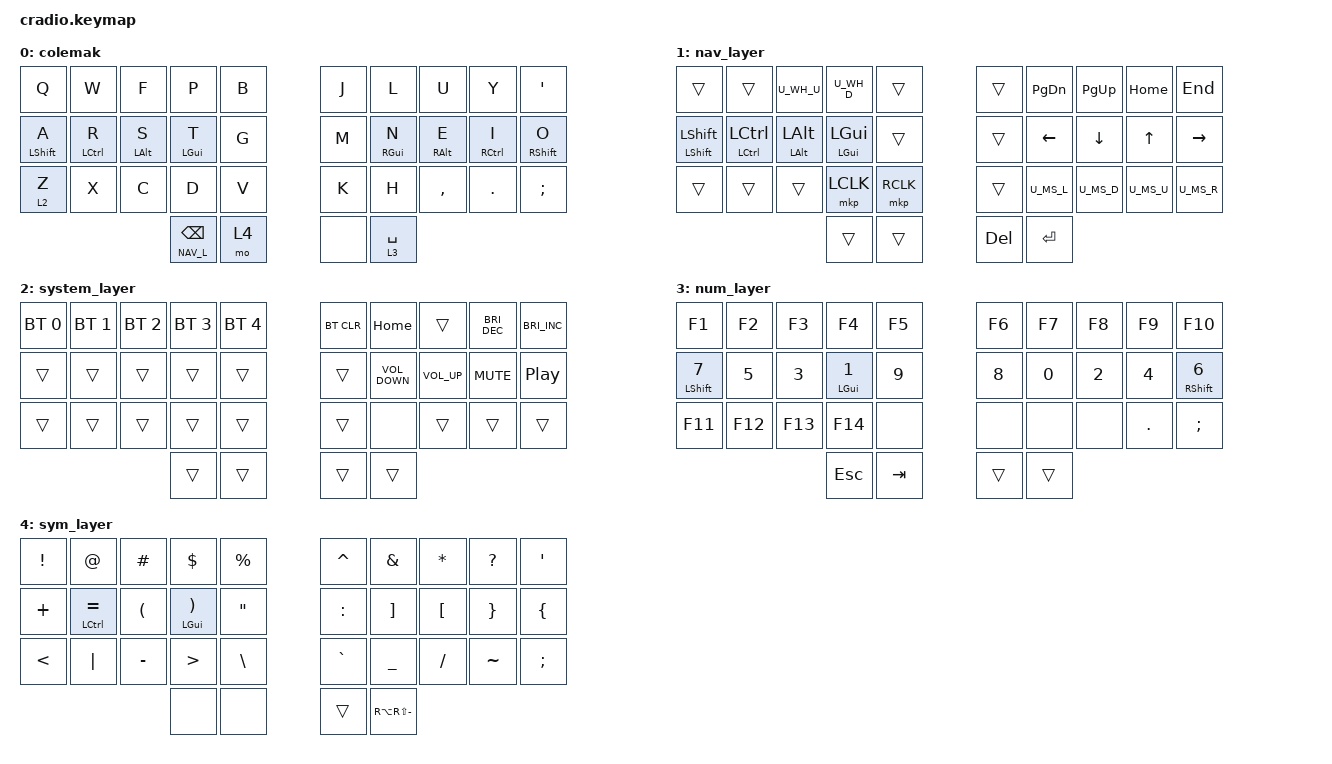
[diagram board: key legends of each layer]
// Copyright (c) 2022 The ZMK Contributors
// SPDX-License-Identifier: MIT

#include <behaviors.dtsi>

// Home row mods macro

#define NAV_L 1
#define OTHER_L 2
#define NUM_L 3
#define SYM_L 4

#include "mouse.dtsi"
#include <dt-bindings/zmk/bt.h>
#include <dt-bindings/zmk/keys.h>

// Using layer taps on thumbs, having quick tap as well helps w/ repeating space/backspace

&lt {
    quick_tap_ms = <200>;
};

/ {
    behaviors {
        hm: homerow_mods {
            compatible = "zmk,behavior-hold-tap";
            label = "homerow mods";
            #binding-cells = <2>;
            tapping_term_ms = <200>;
            flavor = "tap-preferred";
            bindings =
                <&kp>,
                <&kp>;
        };
    };

    keymap {
        compatible = "zmk,keymap";

        colemak {
            bindings = <
&kp Q             &kp W               &kp F           &kp P                &kp B    &kp J  &kp L            &kp U            &kp Y                &kp SQT
&hm LEFT_SHIFT A  &hm LEFT_CONTROL R  &hm LEFT_ALT S  &hm LGUI T           &kp G    &kp M  &hm RIGHT_GUI N  &hm RIGHT_ALT E  &hm RIGHT_CONTROL I  &hm RIGHT_SHIFT O
&lt 2 Z           &kp X               &kp C           &kp D                &kp V    &kp K  &kp H            &kp COMMA        &kp PERIOD           &kp SEMICOLON
                                                      &lt NAV_L BACKSPACE  &mo 4    &none  &lt 3 SPACE
            >;

            label = "colemak";
        };

        nav_layer {
            bindings = <
&trans                     &trans           U_WH_U                 U_WH_D                    &trans      &trans      &kp PAGE_DOWN   &kp PG_UP       &kp HOME      &kp END
&mt LEFT_SHIFT LEFT_SHIFT  &mt LCTRL LCTRL  &mt LEFT_ALT LEFT_ALT  &mt LEFT_GUI LEFT_GUI     &trans      &trans      &kp LEFT_ARROW  &kp DOWN_ARROW  &kp UP_ARROW  &kp RIGHT_ARROW
&trans                     &trans           &trans                 &mkp LCLK                 &mkp RCLK   &trans      U_MS_L          U_MS_D          U_MS_U        U_MS_R
                                            &trans                 &trans                    &kp DELETE  &kp ENTER
            >;
        };

        system_layer {
            bindings = <
&bt BT_SEL 0  &bt BT_SEL 1  &bt BT_SEL 2  &bt BT_SEL 3  &bt BT_SEL 4    &bt BT_CLR  &kp HOME           &trans           &kp C_BRIGHTNESS_DEC  &kp C_BRIGHTNESS_INC
&trans        &trans        &trans        &trans        &trans          &trans      &kp C_VOLUME_DOWN  &kp C_VOLUME_UP  &kp K_MUTE            &kp C_PLAY_PAUSE
&trans        &trans        &trans        &trans        &trans          &trans      &none              &trans           &trans                &trans
                                          &trans        &trans          &trans      &trans
            >;
        };

        num_layer {
            bindings = <
&kp F1             &kp F2        &kp F3        &kp F4                 &kp F5          &kp F6        &kp F7        &kp F8        &kp F9        &kp F10
&hm LEFT_SHIFT N7  &kp NUMBER_5  &kp NUMBER_3  &hm LEFT_GUI NUMBER_1  &kp NUMBER_9    &kp NUMBER_8  &kp NUMBER_0  &kp NUMBER_2  &kp NUMBER_4  &hm RIGHT_SHIFT NUMBER_6
&kp F11            &kp F12       &kp F13       &kp F14                &none           &none         &none         &none         &kp PERIOD    &kp SEMICOLON
                                               &kp ESCAPE             &kp TAB         &trans        &trans
            >;
        };

        sym_layer {
            bindings = <
&kp EXCLAMATION  &kp AT_SIGN               &kp HASH              &kp DOLLAR                      &kp PERCENT          &kp CARET  &kp AMPERSAND      &kp ASTERISK      &kp QUESTION     &kp SINGLE_QUOTE
&kp PLUS         &hm LEFT_CONTROL EQUAL    &kp LEFT_PARENTHESIS  &hm LEFT_GUI RIGHT_PARENTHESIS  &kp DOUBLE_QUOTES    &kp COLON  &kp RIGHT_BRACKET  &kp LEFT_BRACKET  &kp RIGHT_BRACE  &kp LEFT_BRACE
&kp LESS_THAN    &kp PIPE                  &kp MINUS             &kp GREATER_THAN                &kp BACKSLASH        &kp GRAVE  &kp UNDERSCORE     &kp SLASH         &kp TILDE        &kp SEMICOLON
                                                                 &none                           &none                &trans     &kp RA(RS(MINUS))
            >;
        };
    };
};
